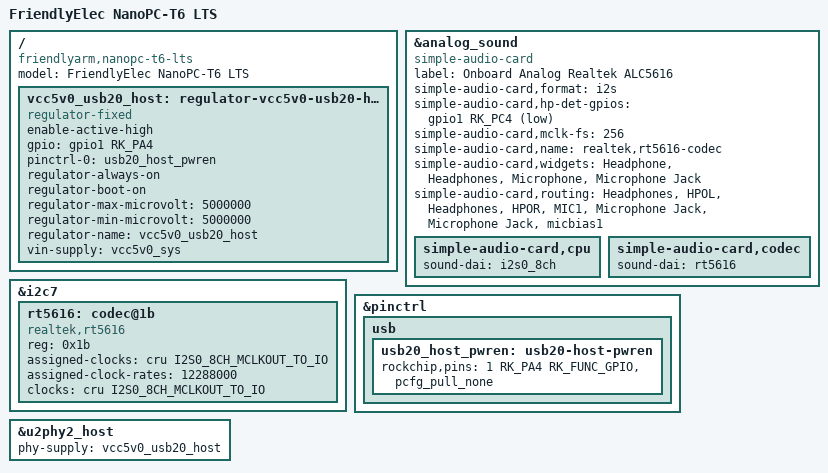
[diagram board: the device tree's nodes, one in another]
// SPDX-License-Identifier: (GPL-2.0+ OR MIT)
/*
 * Copyright (c) 2021 Rockchip Electronics Co., Ltd.
 * Copyright (c) 2023 Thomas McKahan
 * Copyright (c) 2024 Linaro Ltd.
 *
 */

/dts-v1/;

#include "rk3588-nanopc-t6.dtsi"

/ {
	model = "FriendlyElec NanoPC-T6 LTS";
	compatible = "friendlyarm,nanopc-t6-lts", "rockchip,rk3588";

	/* provide power for on-board USB 2.0 hub */
	vcc5v0_usb20_host: regulator-vcc5v0-usb20-host {
		compatible = "regulator-fixed";
		enable-active-high;
		gpio = <&gpio1 RK_PA4 GPIO_ACTIVE_HIGH>;
		pinctrl-0 = <&usb20_host_pwren>;
		pinctrl-names = "default";
		regulator-always-on;
		regulator-boot-on;
		regulator-max-microvolt = <5000000>;
		regulator-min-microvolt = <5000000>;
		regulator-name = "vcc5v0_usb20_host";
		vin-supply = <&vcc5v0_sys>;
	};
};

&analog_sound {
	compatible = "simple-audio-card";
	label = "Onboard Analog Realtek ALC5616";

	simple-audio-card,format = "i2s";
	simple-audio-card,hp-det-gpios = <&gpio1 RK_PC4 GPIO_ACTIVE_LOW>;
	simple-audio-card,mclk-fs = <256>;
	simple-audio-card,name = "realtek,rt5616-codec";

	simple-audio-card,widgets =
		"Headphone", "Headphones",
		"Microphone", "Microphone Jack";
	simple-audio-card,routing =
		"Headphones", "HPOL",
		"Headphones", "HPOR",
		"MIC1", "Microphone Jack",
		"Microphone Jack", "micbias1";

	simple-audio-card,cpu {
		sound-dai = <&i2s0_8ch>;
	};

	simple-audio-card,codec {
		sound-dai = <&rt5616>;
	};
};

&i2c7 {
	rt5616: codec@1b {
		compatible = "realtek,rt5616";
		reg = <0x1b>;
		assigned-clocks = <&cru I2S0_8CH_MCLKOUT_TO_IO>;
		assigned-clock-rates = <12288000>;
		clocks = <&cru I2S0_8CH_MCLKOUT_TO_IO>;
		clock-names = "mclk";
		#sound-dai-cells = <0>;
	};
};

&pinctrl {
	usb {
		usb20_host_pwren: usb20-host-pwren {
			rockchip,pins = <1 RK_PA4 RK_FUNC_GPIO &pcfg_pull_none>;
		};
	};
};

&u2phy2_host {
	phy-supply = <&vcc5v0_usb20_host>;
};
